AUTOSAR XML (schema 4-2-1)
package /WdgM_BswSupervisedEntity
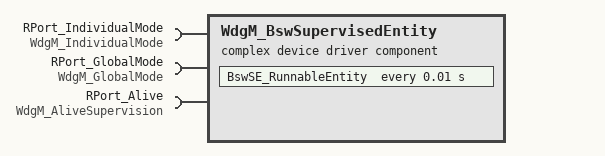
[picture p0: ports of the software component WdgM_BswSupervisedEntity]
  complex device driver sw component type WdgM_BswSupervisedEntity
    require port RPort_IndividualMode: required-interface=WdgM_IndividualMode
    require port RPort_GlobalMode: required-interface=WdgM_GlobalMode
    require port RPort_Alive: required-interface=WdgM_AliveSupervision
    behavior BswSupervisedEntity_IB: data-type-mapping=WdgM_Type_Map
      timing event TimingEvent: start-on-event=BswSE_RunnableEntity, period=0.01
      runnable BswSE_RunnableEntity: mode-access-points=[RPort_GlobalMode.currentMode, RPort_IndividualMode.currentMode], symbol=BswSE_RunnableEntity_func
        sync call SynchronousServerCallPoint_0: operation=RPort_Alive.CheckpointReached
